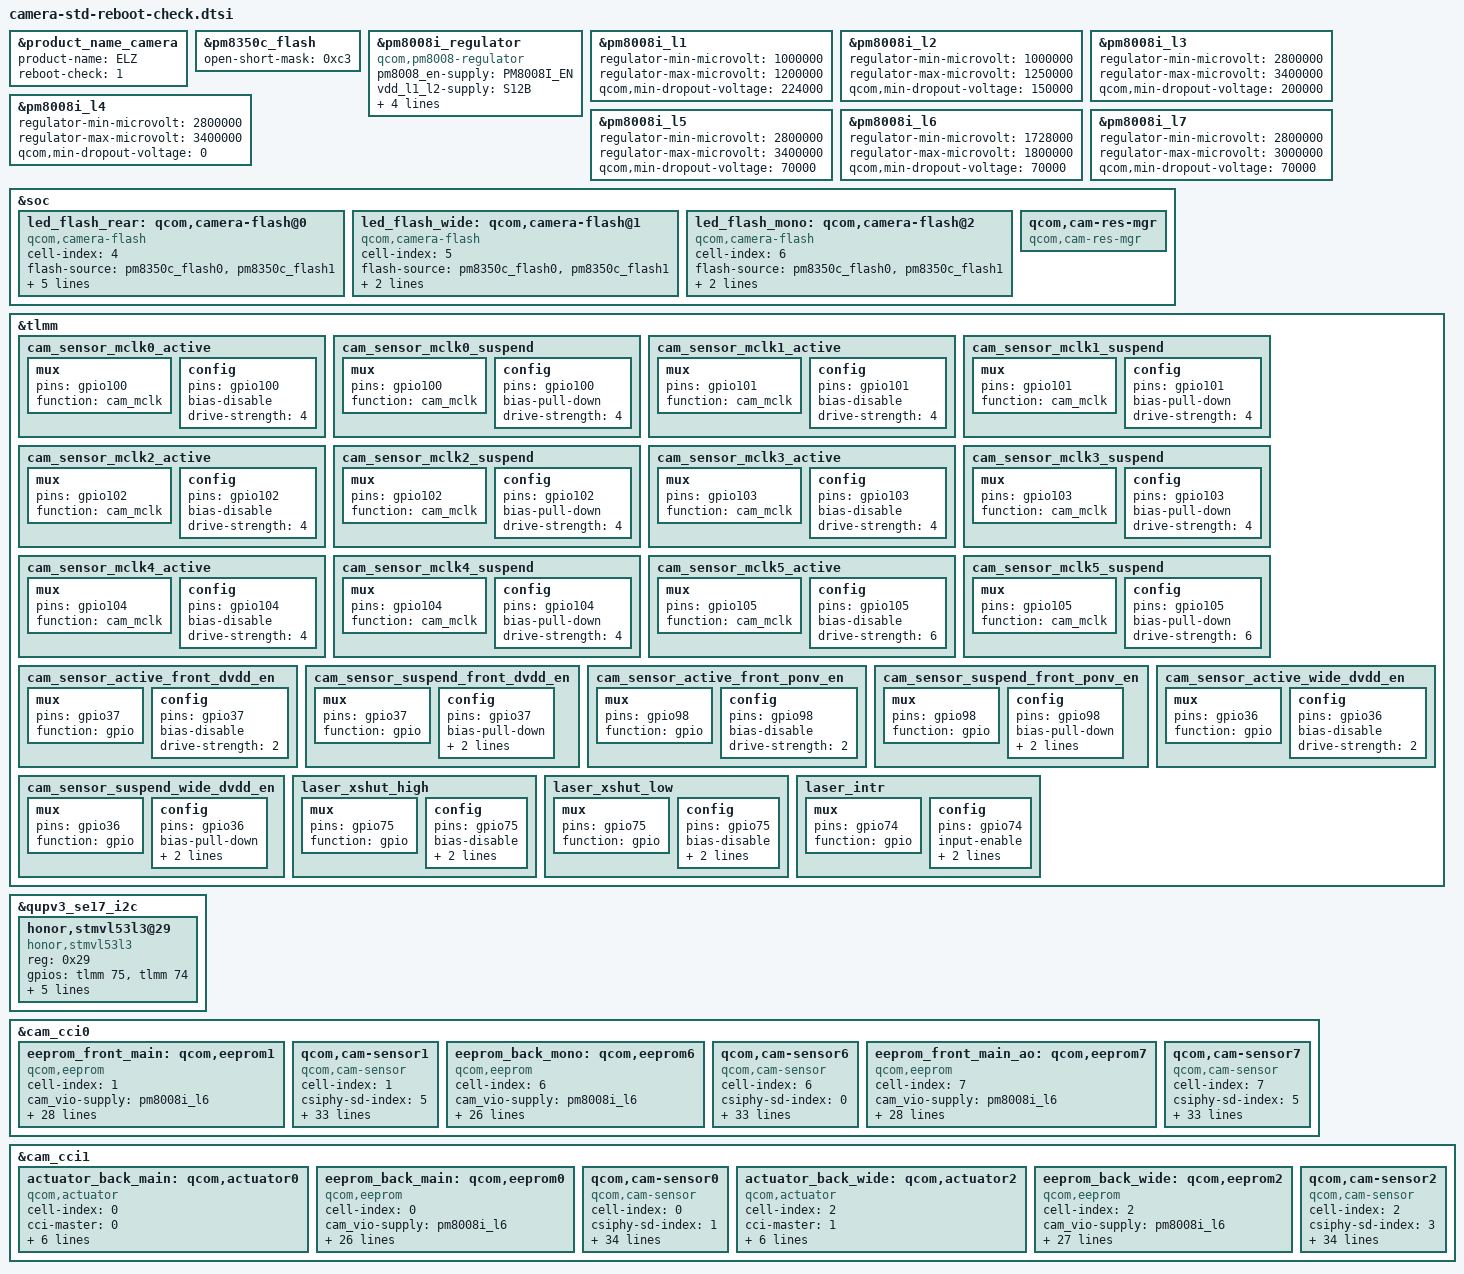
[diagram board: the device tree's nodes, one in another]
#include <dt-bindings/clock/qcom,camcc-lahaina.h>
#include "../isolate-qrd.dtsi"

&product_name_camera {
	product-name = "ELZ";
	reboot-check = "1";
};

&pm8350c_flash {
	open-short-mask = /bits/ 8 <0xc3>;
};

&pm8008i_regulator {
	compatible = "qcom,pm8008-regulator";
	#address-cells = <1>;
	#size-cells = <0>;

	pm8008_en-supply = <&PM8008I_EN>;
	vdd_l1_l2-supply = <&S12B>;
	vdd_l3_l4-supply = <&BOB>;
	vdd_l5-supply = <&BOB>;
	vdd_l6-supply = <&S1C>;
	vdd_l7-supply = <&BOB>;
};

&pm8008i_l1 {
	regulator-min-microvolt = <1000000>;
	regulator-max-microvolt = <1200000>;
	qcom,min-dropout-voltage = <224000>;
};

&pm8008i_l2 {
	regulator-min-microvolt = <1000000>;
	regulator-max-microvolt = <1250000>;
	qcom,min-dropout-voltage = <150000>;
};

&pm8008i_l3 {
	regulator-min-microvolt = <2800000>;
	regulator-max-microvolt = <3400000>;
	qcom,min-dropout-voltage = <200000>;
};

&pm8008i_l4 {
	regulator-min-microvolt = <2800000>;
	regulator-max-microvolt = <3400000>;
	qcom,min-dropout-voltage = <0>;
};

&pm8008i_l5 {
	regulator-min-microvolt = <2800000>;
	regulator-max-microvolt = <3400000>;
	qcom,min-dropout-voltage = <70000>;
};

&pm8008i_l6 {
	regulator-min-microvolt = <1728000>;
	regulator-max-microvolt = <1800000>;
	qcom,min-dropout-voltage = <70000>;
};

&pm8008i_l7 {
	regulator-min-microvolt = <2800000>;
	regulator-max-microvolt = <3000000>;
	qcom,min-dropout-voltage = <70000>;
};

&soc {
	led_flash_rear: qcom,camera-flash@0 {
		cell-index = <4>;
		compatible = "qcom,camera-flash";
		flash-source = <&pm8350c_flash0 &pm8350c_flash1>;
		torch-source = <&pm8350c_torch0 &pm8350c_torch1>;
		switch-source = <&pm8350c_switch2>;
		torch-light-num = <0>;
		torch-light-name = "torch-light0";
		flash_thermal;
		status = "ok";
	};

	led_flash_wide: qcom,camera-flash@1 {
		cell-index = <5>;
		compatible = "qcom,camera-flash";
		flash-source = <&pm8350c_flash0 &pm8350c_flash1>;
		torch-source = <&pm8350c_torch0 &pm8350c_torch1>;
		switch-source = <&pm8350c_switch2>;
		status = "ok";
	};

	led_flash_mono: qcom,camera-flash@2 {
		cell-index = <6>;
		compatible = "qcom,camera-flash";
		flash-source = <&pm8350c_flash0 &pm8350c_flash1>;
		torch-source = <&pm8350c_torch0 &pm8350c_torch1>;
		switch-source = <&pm8350c_switch2>;
		status = "ok";
	};

	qcom,cam-res-mgr {
		compatible = "qcom,cam-res-mgr";
		status = "ok";
	};
};

&tlmm {
	cam_sensor_mclk0_active: cam_sensor_mclk0_active {
		/* MCLK0 */
		mux {
			pins = "gpio100";
			function = "cam_mclk";
		};

		config {
			pins = "gpio100";
			bias-disable; /* No PULL */
			drive-strength = <4>; /* 4 MA */
		};
	};

	cam_sensor_mclk0_suspend: cam_sensor_mclk0_suspend {
		/* MCLK0 */
		mux {
			pins = "gpio100";
			function = "cam_mclk";
		};

		config {
			pins = "gpio100";
			bias-pull-down; /* PULL DOWN */
			drive-strength = <4>; /* 4 MA */
		};
	};

	cam_sensor_mclk1_active: cam_sensor_mclk1_active {
		/* MCLK1 */
		mux {
			pins = "gpio101";
			function = "cam_mclk";
		};

		config {
			pins = "gpio101";
			bias-disable; /* No PULL */
			drive-strength = <4>; /* 4 MA */
		};
	};

	cam_sensor_mclk1_suspend: cam_sensor_mclk1_suspend {
		/* MCLK1 */
		mux {
			pins = "gpio101";
			function = "cam_mclk";
		};

		config {
			pins = "gpio101";
			bias-pull-down; /* PULL DOWN */
			drive-strength = <4>; /* 4 MA */
		};
	};

	cam_sensor_mclk2_active: cam_sensor_mclk2_active {
		/* MCLK2 */
		mux {
			pins = "gpio102";
			function = "cam_mclk";
		};

		config {
			pins = "gpio102";
			bias-disable; /* No PULL */
			drive-strength = <4>; /* 4 MA */
		};
	};

	cam_sensor_mclk2_suspend: cam_sensor_mclk2_suspend {
		/* MCLK2 */
		mux {
			pins = "gpio102";
			function = "cam_mclk";
		};

		config {
			pins = "gpio102";
			bias-pull-down; /* PULL DOWN */
			drive-strength = <4>; /* 4 MA */
		};
	};

	cam_sensor_mclk3_active: cam_sensor_mclk3_active {
		/* MCLK3 */
		mux {
			pins = "gpio103";
			function = "cam_mclk";
		};

		config {
			pins = "gpio103";
			bias-disable; /* No PULL */
			drive-strength = <4>; /* 4 MA */
		};
	};

	cam_sensor_mclk3_suspend: cam_sensor_mclk3_suspend {
		/* MCLK3 */
		mux {
			pins = "gpio103";
			function = "cam_mclk";
		};

		config {
			pins = "gpio103";
			bias-pull-down; /* PULL DOWN */
			drive-strength = <4>; /* 4 MA */
		};
	};

	cam_sensor_mclk4_active: cam_sensor_mclk4_active {
		/* MCLK4 */
		mux {
			pins = "gpio104";
			function = "cam_mclk";
		};

		config {
			pins = "gpio104";
			bias-disable; /* No PULL */
			drive-strength = <4>; /* 4 MA */
		};
	};

	cam_sensor_mclk4_suspend: cam_sensor_mclk4_suspend {
		/* MCLK4 */
		mux {
			pins = "gpio104";
			function = "cam_mclk";
		};

		config {
			pins = "gpio104";
			bias-pull-down; /* PULL DOWN */
			drive-strength = <4>; /* 4 MA */
		};
	};

	cam_sensor_mclk5_active: cam_sensor_mclk5_active {
		/* MCLK5 */
		mux {
			pins = "gpio105";
			function = "cam_mclk";
		};

		config {
			pins = "gpio105";
			bias-disable; /* No PULL */
			drive-strength = <6>; /* 6 MA */
		};
	};

	cam_sensor_mclk5_suspend: cam_sensor_mclk5_suspend {
		/* MCLK5 */
		mux {
			pins = "gpio105";
			function = "cam_mclk";
		};

		config {
			pins = "gpio105";
			bias-pull-down; /* PULL DOWN */
			drive-strength = <6>; /* 6 MA */
		};
	};

	cam_sensor_active_front_dvdd_en: cam_sensor_active_front_dvdd_en {
		/* dvdd enable */
		mux {
			pins = "gpio37";
			function = "gpio";
		};

		config {
			pins = "gpio37";
			bias-disable; /* No PULL */
			drive-strength = <2>; /* 2 MA */
		};
	};

	cam_sensor_suspend_front_dvdd_en: cam_sensor_suspend_front_dvdd_en {
		/* dvdd disable */
		mux {
			pins = "gpio37";
			function = "gpio";
		};

		config {
			pins = "gpio37";
			bias-pull-down; /* PULL DOWN */
			drive-strength = <2>; /* 2 MA */
			output-low;
		};
	};

	cam_sensor_active_front_ponv_en: cam_sensor_active_front_ponv_en {
		/* dvdd enable */
		mux {
			pins = "gpio98";
			function = "gpio";
		};

		config {
			pins = "gpio98";
			bias-disable; /* No PULL */
			drive-strength = <2>; /* 2 MA */
		};
	};

	cam_sensor_suspend_front_ponv_en: cam_sensor_suspend_front_ponv_en {
		/* dvdd disable */
		mux {
			pins = "gpio98";
			function = "gpio";
		};

		config {
			pins = "gpio98";
			bias-pull-down; /* PULL DOWN */
			drive-strength = <2>; /* 2 MA */
			output-low;
		};
	};

	cam_sensor_active_wide_dvdd_en: cam_sensor_active_wide_dvdd_en {
		/* dvdd enable */
		mux {
			pins = "gpio36";
			function = "gpio";
		};

		config {
			pins = "gpio36";
			bias-disable; /* No PULL */
			drive-strength = <2>; /* 2 MA */
		};
	};

	cam_sensor_suspend_wide_dvdd_en: cam_sensor_suspend_wide_dvdd_en {
		/* dvdd disable */
		mux {
			pins = "gpio36";
			function = "gpio";
		};

		config {
			pins = "gpio36";
			bias-pull-down; /* PULL DOWN */
			drive-strength = <2>; /* 2 MA */
			output-low;
		};
	};

	laser_xshut_high: laser_xshut_high {
		/* laser xshut enable */
		mux {
			pins = "gpio75";
			function = "gpio";
		};

		config {
			pins = "gpio75";
			bias-disable; /* No PULL */
			output-high;
			drive-strength = <2>; /* 2 MA */
		};
	};

	laser_xshut_low: laser_xshut_low {
		/* laser xshut disable */
		mux {
			pins = "gpio75";
			function = "gpio";
		};

		config {
			pins = "gpio75";
			bias-disable; /* No PULL */
			output-low;
			drive-strength = <2>; /* 2 MA */
		};
	};

	laser_intr: laser_intr {
		/* laser intr */
		mux {
			pins = "gpio74";
			function = "gpio";
		};

		config {
			pins = "gpio74";
			input-enable;
			bias-pull-up;
			drive-strength = <2>; /* 2 MA */
		};
	};
};

&qupv3_se17_i2c {
	status = "ok";
	honor,stmvl53l3@29 {
		compatible = "honor,stmvl53l3";
		reg = <0x29>;
		gpios = <&tlmm 75 0>,<&tlmm 74 0>;
		honor,gpio-ctrl-types = "xsdn", "intr";
		pinctrl-names = "laser_xshut_high", "laser_xshut_low", "laser_intr";
		pinctrl-0 = <&laser_xshut_high>;
		pinctrl-1 = <&laser_xshut_low>;
		pinctrl-2 = <&laser_intr>;
		laser_state = <1>;
		status = "ok";
	};
};

&cam_cci0 {
	eeprom_front_main: qcom,eeprom1 {
		cell-index = <1>;
		compatible = "qcom,eeprom";
		cam_vio-supply = <&pm8008i_l6>;
		cam_vana-supply = <&pm8008i_l3>;
		cam_clk-supply = <&cam_cc_titan_top_gdsc>;
		regulator-names = "cam_vio", "cam_vana",
			"cam_clk";
		rgltr-cntrl-support;
		rgltr-min-voltage = <1800000 2850000 0>;
		rgltr-max-voltage = <1800000 3000000 0>;
		rgltr-load-current = <5000 68000 0>;
		gpio-no-mux = <0>;
		pinctrl-names = "cam_default", "cam_suspend";
		pinctrl-0 = <&cam_sensor_mclk5_active
				&cam_sensor_active_rst5
				&cam_sensor_active_front_dvdd_en
				&cam_sensor_active_front_ponv_en>;
		pinctrl-1 = <&cam_sensor_mclk5_suspend
				&cam_sensor_suspend_rst5
				&cam_sensor_suspend_front_dvdd_en
				&cam_sensor_suspend_front_ponv_en>;
		gpios = <&tlmm 105 0>,
			<&tlmm 115 0>,
			<&tlmm 37 0>,
			<&tlmm 98 0>;
		gpio-reset = <1>;
		gpio-custom1 = <2>;
		gpio-custom2 = <3>;
		gpio-req-tbl-num = <0 1 2 3>;
		gpio-req-tbl-flags = <1 0 0 0>;
		gpio-req-tbl-label = "CAMIF_MCLK5",
					"CAM_RESET5",
					"CAM_DVDD_EN",
					"CAM_PONV";
		cci-master = <0>;
		status = "ok";
		clocks = <&clock_camcc CAM_CC_MCLK5_CLK>;
		clock-names = "cam_clk";
		clock-cntl-level = "nominal";
		clock-rates = <24000000>;
	};

	/* Front */
	qcom,cam-sensor1 {
		cell-index = <1>;
		compatible = "qcom,cam-sensor";
		csiphy-sd-index = <5>;
		sensor-position-roll = <270>;
		sensor-position-pitch = <0>;
		sensor-position-yaw = <0>;
		eeprom-src = <&eeprom_front_main>;
		cam_vio-supply = <&pm8008i_l6>;
		cam_vana-supply = <&pm8008i_l3>;
		cam_clk-supply = <&cam_cc_titan_top_gdsc>;
		regulator-names = "cam_vio", "cam_vana",
			"cam_clk";
		rgltr-cntrl-support;
		rgltr-min-voltage = <1800000 2850000 0>;
		rgltr-max-voltage = <1800000 3000000 0>;
		rgltr-load-current = <40000 80000 0>;
		gpio-no-mux = <0>;
		pinctrl-names = "cam_default", "cam_suspend";
		pinctrl-0 = <&cam_sensor_mclk5_active
				&cam_sensor_active_rst5
				&cam_sensor_active_front_dvdd_en
				&cam_sensor_active_front_ponv_en>;
		pinctrl-1 = <&cam_sensor_mclk5_suspend
				&cam_sensor_suspend_rst5
				&cam_sensor_suspend_front_dvdd_en
				&cam_sensor_suspend_front_ponv_en>;
		gpios = <&tlmm 105 0>,
			<&tlmm 115 0>,
			<&tlmm 37 0>,
			<&tlmm 98 0>;
		gpio-reset = <1>;
		gpio-custom1 = <2>;
		gpio-custom2 = <3>;
		gpio-req-tbl-num = <0 1 2 3>;
		gpio-req-tbl-flags = <1 0 0 0>;
		gpio-req-tbl-label = "CAMIF_MCLK5",
					"CAM_RESET5",
					"CAM_DVDD_EN",
					"CAM_PONV";
		cci-master = <0>;
		status = "ok";
		clocks = <&clock_camcc CAM_CC_MCLK5_CLK>;
		clock-names = "cam_clk";
		clock-cntl-level = "nominal";
		clock-rates = <24000000>;
	};

	/* back mono */
	eeprom_back_mono: qcom,eeprom6 {
		cell-index = <6>;
		compatible = "qcom,eeprom";
		cam_vio-supply = <&pm8008i_l6>;
		cam_vana-supply = <&pm8008i_l7>;
		cam_vdig-supply = <&pm8008i_l1>;
		cam_clk-supply = <&cam_cc_titan_top_gdsc>;
		cam_v_custom1-supply = <&pm8008i_l4>; /* afvdd */
		regulator-names = "cam_vio", "cam_vana",
			"cam_vdig", "cam_clk", "cam_v_custom1";
		rgltr-cntrl-support;
		rgltr-min-voltage = <1800000 2850000 1104000 0 3300000>;
		rgltr-max-voltage = <1800000 3000000 1104000 0 3300000>;
		rgltr-load-current = <5000 68000 805000 0 68000>;
		gpio-no-mux = <0>;
		pinctrl-names = "cam_default", "cam_suspend";
		pinctrl-0 = <&cam_sensor_mclk0_active
				&cam_sensor_active_rst1>;
		pinctrl-1 = <&cam_sensor_mclk0_suspend
				&cam_sensor_suspend_rst1>;
		gpios = <&tlmm 100 0>,
			<&tlmm 16 0>;
		gpio-reset = <1>;
		gpio-req-tbl-num = <0 1>;
		gpio-req-tbl-flags = <1 0>;
		gpio-req-tbl-label = "CAMIF_MCLK0",
					"CAM_RESET1";
		cci-master = <1>;
		status = "ok";
		clocks = <&clock_camcc CAM_CC_MCLK0_CLK>;
		clock-names = "cam_clk";
		clock-cntl-level = "nominal";
		clock-rates = <24000000>;
	};

	qcom,cam-sensor6 {
		cell-index = <6>;
		compatible = "qcom,cam-sensor";
		csiphy-sd-index = <0>;
		sensor-position-roll = <90>;
		sensor-position-pitch = <0>;
		sensor-position-yaw = <180>;
		eeprom-src = <&eeprom_back_mono>;
		led-flash-src = <&led_flash_mono>;
		cam_vio-supply = <&pm8008i_l6>;
		cam_vana-supply = <&pm8008i_l7>;
		cam_vdig-supply = <&pm8008i_l1>;
		cam_clk-supply = <&cam_cc_titan_top_gdsc>;
		cam_v_custom1-supply = <&pm8008i_l4>; /* afvdd */
		regulator-names = "cam_vio", "cam_vana",
			"cam_vdig", "cam_clk", "cam_v_custom1";
		rgltr-cntrl-support;
		rgltr-min-voltage = <1800000 2850000 1104000 0 3300000>;
		rgltr-max-voltage = <1800000 3000000 1104000 0 3300000>;
		rgltr-load-current = <20000 128000 800000 0 110000>;
		gpio-no-mux = <0>;
		pinctrl-names = "cam_default", "cam_suspend";
		pinctrl-0 = <&cam_sensor_mclk0_active
				&cam_sensor_active_rst1>;
		pinctrl-1 = <&cam_sensor_mclk0_suspend
				&cam_sensor_suspend_rst1>;
		gpios = <&tlmm 100 0>,
			<&tlmm 16 0>;
		gpio-reset = <1>;
		gpio-req-tbl-num = <0 1>;
		gpio-req-tbl-flags = <1 0>;
		gpio-req-tbl-label = "CAMIF_MCLK0",
					"CAM_RESET1";
		cci-master = <1>;
		status = "ok";
		clocks = <&clock_camcc CAM_CC_MCLK0_CLK>;
		clock-names = "cam_clk";
		clock-cntl-level = "nominal";
		clock-rates = <24000000>;
	};

	eeprom_front_main_ao: qcom,eeprom7 {
		cell-index = <7>;
		compatible = "qcom,eeprom";
		cam_vio-supply = <&pm8008i_l6>;
		cam_vana-supply = <&pm8008i_l3>;
		cam_clk-supply = <&cam_cc_titan_top_gdsc>;
		regulator-names = "cam_vio", "cam_vana",
			"cam_clk";
		rgltr-cntrl-support;
		rgltr-min-voltage = <1800000 2850000 0>;
		rgltr-max-voltage = <1800000 3000000 0>;
		rgltr-load-current = <5000 68000 0>;
		gpio-no-mux = <0>;
		pinctrl-names = "cam_default", "cam_suspend";
		pinctrl-0 = <&cam_sensor_mclk5_active
				&cam_sensor_active_rst5
				&cam_sensor_active_front_dvdd_en
				&cam_sensor_active_front_ponv_en>;
		pinctrl-1 = <&cam_sensor_mclk5_suspend
				&cam_sensor_suspend_rst5
				&cam_sensor_suspend_front_dvdd_en
				&cam_sensor_suspend_front_ponv_en>;
		gpios = <&tlmm 105 0>,
			<&tlmm 115 0>,
			<&tlmm 37 0>,
			<&tlmm 98 0>;
		gpio-reset = <1>;
		gpio-custom1 = <2>;
		gpio-custom2 = <3>;
		gpio-req-tbl-num = <0 1 2 3>;
		gpio-req-tbl-flags = <1 0 0 0>;
		gpio-req-tbl-label = "CAMIF_MCLK5",
					"CAM_RESET5",
					"CAM_DVDD_EN",
					"CAM_PONV";
		cci-master = <0>;
		status = "ok";
		clocks = <&clock_camcc CAM_CC_MCLK5_CLK>;
		clock-names = "cam_clk";
		clock-cntl-level = "nominal";
		clock-rates = <24000000>;
	};

	/* Front */
	qcom,cam-sensor7 {
		cell-index = <7>;
		compatible = "qcom,cam-sensor";
		csiphy-sd-index = <5>;
		sensor-position-roll = <270>;
		sensor-position-pitch = <0>;
		sensor-position-yaw = <0>;
		eeprom-src = <&eeprom_front_main_ao>;
		cam_vio-supply = <&pm8008i_l6>;
		cam_vana-supply = <&pm8008i_l3>;
		cam_clk-supply = <&cam_cc_titan_top_gdsc>;
		regulator-names = "cam_vio", "cam_vana",
			"cam_clk";
		rgltr-cntrl-support;
		rgltr-min-voltage = <1800000 2850000 0>;
		rgltr-max-voltage = <1800000 3000000 0>;
		rgltr-load-current = <5000 68000 0>;
		gpio-no-mux = <0>;
		pinctrl-names = "cam_default", "cam_suspend";
		pinctrl-0 = <&cam_sensor_mclk5_active
				&cam_sensor_active_rst5
				&cam_sensor_active_front_dvdd_en
				&cam_sensor_active_front_ponv_en>;
		pinctrl-1 = <&cam_sensor_mclk5_suspend
				&cam_sensor_suspend_rst5
				&cam_sensor_suspend_front_dvdd_en
				&cam_sensor_suspend_front_ponv_en>;
		gpios = <&tlmm 105 0>,
			<&tlmm 115 0>,
			<&tlmm 37 0>,
			<&tlmm 98 0>;
		gpio-reset = <1>;
		gpio-custom1 = <2>;
		gpio-custom2 = <3>;
		gpio-req-tbl-num = <0 1 2 3>;
		gpio-req-tbl-flags = <1 0 0 0>;
		gpio-req-tbl-label = "CAMIF_MCLK5",
					"CAM_RESET5",
					"CAM_DVDD_EN",
					"CAM_PONV";
		cci-master = <0>;
		status = "ok";
		clocks = <&clock_camcc CAM_CC_MCLK5_CLK>;
		clock-names = "cam_clk";
		clock-cntl-level = "nominal";
		clock-rates = <24000000>;
	};
};

&cam_cci1 {
	/* back main */
	actuator_back_main: qcom,actuator0 {
		cell-index = <0>;
		compatible = "qcom,actuator";
		cci-master = <0>;
		cam_vaf-supply = <&pm8008i_l4>;
		regulator-names = "cam_vaf";
		rgltr-cntrl-support;
		rgltr-min-voltage = <3300000>;
		rgltr-max-voltage = <3300000>;
		rgltr-load-current = <68000>;
		status = "ok";
	};

	eeprom_back_main: qcom,eeprom0 {
		cell-index = <0>;
		compatible = "qcom,eeprom";
		cam_vio-supply = <&pm8008i_l6>;
		cam_vana-supply = <&pm8008i_l5>;
		cam_vdig-supply = <&pm8008i_l2>;
		cam_clk-supply = <&cam_cc_titan_top_gdsc>;
		cam_v_custom1-supply = <&pm8008i_l4>; /* afvdd */
		regulator-names = "cam_vio", "cam_vana",
			"cam_vdig", "cam_clk", "cam_v_custom1";
		rgltr-cntrl-support;
		rgltr-min-voltage = <1800000 2850000 1150000 0 3300000>;
		rgltr-max-voltage = <1800000 3000000 1200000 0 3300000>;
		rgltr-load-current = <5000 68000 805000 0 68000>;
		gpio-no-mux = <0>;
		pinctrl-names = "cam_default", "cam_suspend";
		pinctrl-0 = <&cam_sensor_mclk1_active
				&cam_sensor_active_rst0>;
		pinctrl-1 = <&cam_sensor_mclk1_suspend
				&cam_sensor_suspend_rst0>;
		gpios = <&tlmm 101 0>,
			<&tlmm 17 0>;
		gpio-reset = <1>;
		gpio-req-tbl-num = <0 1>;
		gpio-req-tbl-flags = <1 0>;
		gpio-req-tbl-label = "CAMIF_MCLK1",
					"CAM_RESET0";
		cci-master = <0>;
		status = "ok";
		clocks = <&clock_camcc CAM_CC_MCLK1_CLK>;
		clock-names = "cam_clk";
		clock-cntl-level = "nominal";
		clock-rates = <24000000>;
	};

	qcom,cam-sensor0 {
		cell-index = <0>;
		compatible = "qcom,cam-sensor";
		csiphy-sd-index = <1>;
		sensor-position-roll = <90>;
		sensor-position-pitch = <0>;
		sensor-position-yaw = <180>;
		eeprom-src = <&eeprom_back_main>;
		actuator-src = <&actuator_back_main>;
		led-flash-src = <&led_flash_rear>;
		cam_vio-supply = <&pm8008i_l6>;
		cam_vana-supply = <&pm8008i_l5>;
		cam_vdig-supply = <&pm8008i_l2>;
		cam_clk-supply = <&cam_cc_titan_top_gdsc>;
		cam_v_custom1-supply = <&pm8008i_l4>; /* afvdd */
		regulator-names = "cam_vio", "cam_vana",
			"cam_vdig", "cam_clk", "cam_v_custom1";
		rgltr-cntrl-support;
		rgltr-min-voltage = <1800000 2850000 1150000 0 3300000>;
		rgltr-max-voltage = <1800000 3000000 1200000 0 3300000>;
		rgltr-load-current = <80000 100000 913000 0 110000>;
		gpio-no-mux = <0>;
		pinctrl-names = "cam_default", "cam_suspend";
		pinctrl-0 = <&cam_sensor_mclk1_active
				&cam_sensor_active_rst0>;
		pinctrl-1 = <&cam_sensor_mclk1_suspend
				&cam_sensor_suspend_rst0>;
		gpios = <&tlmm 101 0>,
			<&tlmm 17 0>;
		gpio-reset = <1>;
		gpio-req-tbl-num = <0 1>;
		gpio-req-tbl-flags = <1 0>;
		gpio-req-tbl-label = "CAMIF_MCLK1",
					"CAM_RESET0";
		cci-master = <0>;
		status = "ok";
		clocks = <&clock_camcc CAM_CC_MCLK1_CLK>;
		clock-names = "cam_clk";
		clock-cntl-level = "nominal";
		clock-rates = <24000000>;
	};

	/* back wide */
	actuator_back_wide: qcom,actuator2 {
		cell-index = <2>;
		compatible = "qcom,actuator";
		cci-master = <1>;
		cam_vaf-supply = <&pm8008i_l4>;
		regulator-names = "cam_vaf";
		rgltr-cntrl-support;
		rgltr-min-voltage = <3300000>;
		rgltr-max-voltage = <3300000>;
		rgltr-load-current = <68000>;
		status = "ok";
	};

	eeprom_back_wide: qcom,eeprom2 {
		cell-index = <2>;
		compatible = "qcom,eeprom";
		cam_vio-supply = <&pm8008i_l6>;
		cam_vana-supply = <&pm8008i_l7>;
		cam_clk-supply = <&cam_cc_titan_top_gdsc>;
		cam_v_custom1-supply = <&pm8008i_l4>; /* afvdd */
		regulator-names = "cam_vio", "cam_vana",
			"cam_clk", "cam_v_custom1";
		rgltr-cntrl-support;
		rgltr-min-voltage = <1800000 2850000 0 3300000>;
		rgltr-max-voltage = <1800000 3000000 0 3300000>;
		rgltr-load-current = <5000 68000 0 68000>;
		gpio-no-mux = <0>;
		pinctrl-names = "cam_default", "cam_suspend";
		pinctrl-0 = <&cam_sensor_mclk3_active
				&cam_sensor_active_rst3
				&cam_sensor_active_wide_dvdd_en>;
		pinctrl-1 = <&cam_sensor_mclk3_suspend
				&cam_sensor_suspend_rst3
				&cam_sensor_suspend_wide_dvdd_en>;
		gpios = <&tlmm 103 0>,
			<&tlmm 117 0>,
			<&tlmm 36 0>;
		gpio-reset = <1>;
		gpio-custom1 = <2>;
		gpio-req-tbl-num = <0 1 2>;
		gpio-req-tbl-flags = <1 0 0>;
		gpio-req-tbl-label = "CAMIF_MCLK3",
					"CAM_RESET3",
					"CAM_DVDD_EN";
		cci-master = <1>;
		status = "ok";
		clocks = <&clock_camcc CAM_CC_MCLK3_CLK>;
		clock-names = "cam_clk";
		clock-cntl-level = "nominal";
		clock-rates = <24000000>;
	};

	/* back wide */
	qcom,cam-sensor2 {
		cell-index = <2>;
		compatible = "qcom,cam-sensor";
		csiphy-sd-index = <3>;
		sensor-position-roll = <90>;
		sensor-position-pitch = <0>;
		sensor-position-yaw = <180>;
		eeprom-src = <&eeprom_back_wide>;
		actuator-src = <&actuator_back_wide>;
		led-flash-src = <&led_flash_wide>;
		cam_vio-supply = <&pm8008i_l6>;
		cam_vana-supply = <&pm8008i_l7>;
		cam_clk-supply = <&cam_cc_titan_top_gdsc>;
		cam_v_custom1-supply = <&pm8008i_l4>; /* afvdd */
		regulator-names = "cam_vio", "cam_vana",
			"cam_clk", "cam_v_custom1";
		rgltr-cntrl-support;
		rgltr-min-voltage = <1800000 2850000 0 3300000>;
		rgltr-max-voltage = <1800000 3000000 0 3300000>;
		rgltr-load-current = <60000 80000 0 110000>;
		gpio-no-mux = <0>;
		pinctrl-names = "cam_default", "cam_suspend";
		pinctrl-0 = <&cam_sensor_mclk3_active
				&cam_sensor_active_rst3
				&cam_sensor_active_wide_dvdd_en>;
		pinctrl-1 = <&cam_sensor_mclk3_suspend
				&cam_sensor_suspend_rst3
				&cam_sensor_suspend_wide_dvdd_en>;
		gpios = <&tlmm 103 0>,
			<&tlmm 117 0>,
			<&tlmm 36 0>;
		gpio-reset = <1>;
		gpio-custom1 = <2>;
		gpio-req-tbl-num = <0 1 2>;
		gpio-req-tbl-flags = <1 0 0>;
		gpio-req-tbl-label = "CAMIF_MCLK3",
					"CAM_RESET3",
					"CAM_DVDD_EN";
		cci-master = <1>;
		status = "ok";
		clocks = <&clock_camcc CAM_CC_MCLK3_CLK>;
		clock-names = "cam_clk";
		clock-cntl-level = "nominal";
		clock-rates = <24000000>;
	};
};
